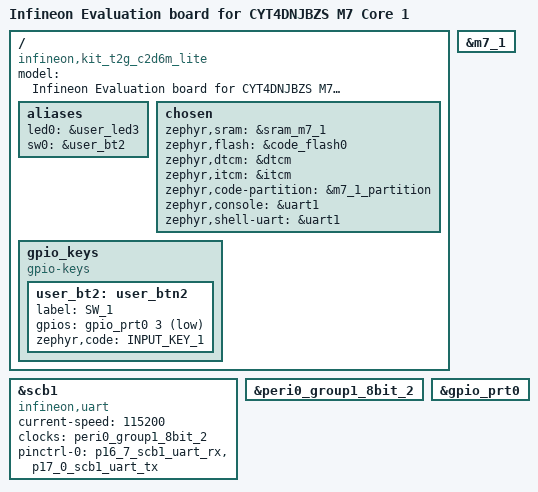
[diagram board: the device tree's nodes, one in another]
/*
 * SPDX-FileCopyrightText: Copyright (c) 2026 Linumiz
 *
 * SPDX-License-Identifier: Apache-2.0
 */

/dts-v1/;
#include <arm/infineon/cat1c/traveo/cyt4dn/cyt4dn_m7.dtsi>
#include "kit_t2g_c2d6m_lite_common.dtsi"

/ {
	model = "Infineon Evaluation board for CYT4DNJBZS M7 Core 1";
	compatible = "infineon,kit_t2g_c2d6m_lite", "infineon,cyt4dn";

	aliases {
		led0 = &user_led3;
		sw0 = &user_bt2;
	};

	chosen {
		zephyr,sram = &sram_m7_1;
		zephyr,flash = &code_flash0;
		zephyr,dtcm = &dtcm;
		zephyr,itcm = &itcm;
		zephyr,code-partition = &m7_1_partition;
		zephyr,console = &uart1;
		zephyr,shell-uart = &uart1;
	};

	gpio_keys {
		compatible = "gpio-keys";

		user_bt2: user_btn2 {
			label = "SW_1";
			gpios = <&gpio_prt0 3 (GPIO_PULL_UP | GPIO_ACTIVE_LOW)>;
			zephyr,code = <INPUT_KEY_1>;
		};
	};
};

&m7_1 {
	status = "okay";
};

/*
 * This board exposes only two UARTs (SCB7, SCB9), used by M7_0 and M0+.
 * SCB1 is assigned to M7_1 so its console does not clash with a UART
 * used by another core; change it to any free SCB if needed.
 */
uart1: &scb1 {
	compatible = "infineon,uart";
	current-speed = <115200>;
	clocks = <&peri0_group1_8bit_2>;

	pinctrl-0 = <&p16_7_scb1_uart_rx &p17_0_scb1_uart_tx>;
	pinctrl-names = "default";
	status = "okay";
};

&peri0_group1_8bit_2 {
	status = "okay";
};

&gpio_prt0 {
	status = "okay";
};
